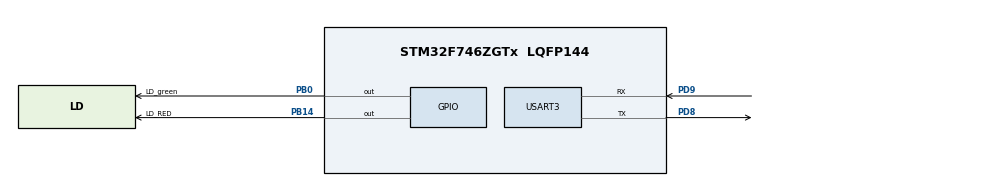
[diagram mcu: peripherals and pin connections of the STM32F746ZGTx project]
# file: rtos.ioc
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FREERTOS.Tasks01=BLINK_ld_green,24,128,StartBlind_ld_green,Default,NULL,Dynamic,NULL,NULL;blind_ld_red,17,128,Start_blink_ld_red,Default,NULL,Dynamic,NULL,NULL
Mcu.Family=STM32F7
Mcu.Name=STM32F746ZGTx
Mcu.Package=LQFP144
NVIC.PriorityGroup=NVIC_PRIORITYGROUP_4
NVIC.TIM6_DAC_IRQn=true\:15\:0\:false\:false\:true\:false\:false\:true\:true
NVIC.TimeBase=TIM6_DAC_IRQn
NVIC.TimeBaseIP=TIM6
PB0.GPIO_Label=LD_green
PB0.Signal=GPIO_Output
PB14.GPIO_Label=LD_RED
PB14.Signal=GPIO_Output
PD8.Mode=Asynchronous
PD8.Signal=USART3_TX
PD9.Mode=Asynchronous
PD9.Signal=USART3_RX
ProjectManager.HeapSize=0x200
ProjectManager.StackSize=0x400
ProjectManager.TargetToolchain=STM32CubeIDE
RCC.HSE_VALUE=25000000
RCC.HSI_VALUE=16000000
RCC.LSE_VALUE=32768
RCC.USBFreq_Value=96000000
RCC.VCOOutputFreq_Value=192000000
USART3.VirtualMode-Asynchronous=VM_ASYNC
VP_FREERTOS_VS_CMSIS_V2.Mode=CMSIS_V2
VP_SYS_VS_tim6.Mode=TIM6
board=custom

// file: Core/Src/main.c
/* USER CODE BEGIN Header */
/**
  ******************************************************************************
  * @file           : main.c
  * @brief          : Main program body
  ******************************************************************************
  * @attention
  *
  * Copyright (c) 2022 STMicroelectronics.
  * All rights reserved.
  *
  * This software is licensed under terms that can be found in the LICENSE file
  * in the root directory of this software component.
  * If no LICENSE file comes with this software, it is provided AS-IS.
  *
  ******************************************************************************
  */
/* USER CODE END Header */
#include "main.h"
#include "cmsis_os.h"

UART_HandleTypeDef huart3;

/* Definitions for BLINK_ld_green */
osThreadId_t BLINK_ld_greenHandle;
const osThreadAttr_t BLINK_ld_green_attributes = {
  .name = "BLINK_ld_green",
  .stack_size = 128 * 4,
  .priority = (osPriority_t) osPriorityNormal,
};
/* Definitions for blind_ld_red */
osThreadId_t blind_ld_redHandle;
const osThreadAttr_t blind_ld_red_attributes = {
  .name = "blind_ld_red",
  .stack_size = 128 * 4,
  .priority = (osPriority_t) osPriorityBelowNormal1,
};

void SystemClock_Config(void);
static void MX_GPIO_Init(void);
static void MX_USART3_UART_Init(void);
void StartBlind_ld_green(void *argument);
void Start_blink_ld_red(void *argument);

int main(void)
{

  /* MCU Configuration--------------------------------------------------------*/

  /* Reset of all peripherals, Initializes the Flash interface and the Systick. */
  HAL_Init();

  /* Configure the system clock */
  SystemClock_Config();

  /* Initialize all configured peripherals */
  MX_GPIO_Init();
  MX_USART3_UART_Init();

  /* Init scheduler */
  osKernelInitialize();

  /* Create the thread(s) */
  /* creation of BLINK_ld_green */
  BLINK_ld_greenHandle = osThreadNew(StartBlind_ld_green, NULL, &BLINK_ld_green_attributes);

  /* creation of blind_ld_red */
  blind_ld_redHandle = osThreadNew(Start_blink_ld_red, NULL, &blind_ld_red_attributes);

  /* Start scheduler */
  osKernelStart();

  /* We should never get here as control is now taken by the scheduler */
  /* Infinite loop */
  while (1)
  {

  }
}

void SystemClock_Config(void)
{
  RCC_OscInitTypeDef RCC_OscInitStruct = {0};
  RCC_ClkInitTypeDef RCC_ClkInitStruct = {0};

  /** Configure the main internal regulator output voltage
  */
  __HAL_RCC_PWR_CLK_ENABLE();
  __HAL_PWR_VOLTAGESCALING_CONFIG(PWR_REGULATOR_VOLTAGE_SCALE3);

  /** Initializes the RCC Oscillators according to the specified parameters
  * in the RCC_OscInitTypeDef structure.
  */
  RCC_OscInitStruct.OscillatorType = RCC_OSCILLATORTYPE_HSI;
  RCC_OscInitStruct.HSIState = RCC_HSI_ON;
  RCC_OscInitStruct.HSICalibrationValue = RCC_HSICALIBRATION_DEFAULT;
  RCC_OscInitStruct.PLL.PLLState = RCC_PLL_NONE;
  if (HAL_RCC_OscConfig(&RCC_OscInitStruct) != HAL_OK)
  {
    Error_Handler();
  }

  /** Initializes the CPU, AHB and APB buses clocks
  */
  RCC_ClkInitStruct.ClockType = RCC_CLOCKTYPE_HCLK|RCC_CLOCKTYPE_SYSCLK
                              |RCC_CLOCKTYPE_PCLK1|RCC_CLOCKTYPE_PCLK2;
  RCC_ClkInitStruct.SYSCLKSource = RCC_SYSCLKSOURCE_HSI;
  RCC_ClkInitStruct.AHBCLKDivider = RCC_SYSCLK_DIV1;
  RCC_ClkInitStruct.APB1CLKDivider = RCC_HCLK_DIV1;
  RCC_ClkInitStruct.APB2CLKDivider = RCC_HCLK_DIV1;

  if (HAL_RCC_ClockConfig(&RCC_ClkInitStruct, FLASH_LATENCY_0) != HAL_OK)
  {
    Error_Handler();
  }
}

static void MX_USART3_UART_Init(void)
{

  huart3.Instance = USART3;
  huart3.Init.BaudRate = 115200;
  huart3.Init.WordLength = UART_WORDLENGTH_8B;
  huart3.Init.StopBits = UART_STOPBITS_1;
  huart3.Init.Parity = UART_PARITY_NONE;
  huart3.Init.Mode = UART_MODE_TX_RX;
  huart3.Init.HwFlowCtl = UART_HWCONTROL_NONE;
  huart3.Init.OverSampling = UART_OVERSAMPLING_16;
  huart3.Init.OneBitSampling = UART_ONE_BIT_SAMPLE_DISABLE;
  huart3.AdvancedInit.AdvFeatureInit = UART_ADVFEATURE_NO_INIT;
  if (HAL_UART_Init(&huart3) != HAL_OK)
  {
    Error_Handler();
  }

}

static void MX_GPIO_Init(void)
{
  GPIO_InitTypeDef GPIO_InitStruct = {0};

  /* GPIO Ports Clock Enable */
  __HAL_RCC_GPIOB_CLK_ENABLE();
  __HAL_RCC_GPIOD_CLK_ENABLE();

  /*Configure GPIO pin Output Level */
  HAL_GPIO_WritePin(GPIOB, LD_green_Pin|LD_RED_Pin, GPIO_PIN_RESET);

  /*Configure GPIO pins : LD_green_Pin LD_RED_Pin */
  GPIO_InitStruct.Pin = LD_green_Pin|LD_RED_Pin;
  GPIO_InitStruct.Mode = GPIO_MODE_OUTPUT_PP;
  GPIO_InitStruct.Pull = GPIO_NOPULL;
  GPIO_InitStruct.Speed = GPIO_SPEED_FREQ_LOW;
  HAL_GPIO_Init(GPIOB, &GPIO_InitStruct);

}

void StartBlind_ld_green(void *argument)
{
  /* USER CODE BEGIN 5 */
  /* Infinite loop */
  for(;;)
  {
    HAL_GPIO_TogglePin(LD_green_GPIO_Port, LD_green_Pin);
	  osDelay(1000);
  }
  /* USER CODE END 5 */
}

void Start_blink_ld_red(void *argument)
{
  /* USER CODE BEGIN Start_blink_ld_red */
  /* Infinite loop */
  for(;;)
  {
	  HAL_GPIO_TogglePin(LD_RED_GPIO_Port, LD_RED_Pin);
    osDelay(500);
  }
  /* USER CODE END Start_blink_ld_red */
}

void HAL_TIM_PeriodElapsedCallback(TIM_HandleTypeDef *htim)
{
  if (htim->Instance == TIM6) {
    HAL_IncTick();
  }
}

void Error_Handler(void)
{
  __disable_irq();
  while (1)
  {
  }
}
